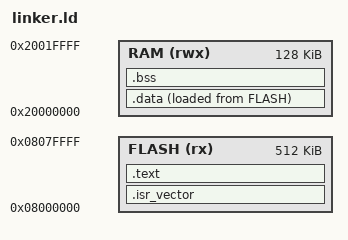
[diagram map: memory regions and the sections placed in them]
ENTRY(_start)

MEMORY
{
    FLASH (rx)  : ORIGIN = 0x08000000, LENGTH = 512K
    RAM   (rwx) : ORIGIN = 0x20000000, LENGTH = 128K
}

SECTIONS
{
    .isr_vector :
    {
        . = ALIGN(4);
        KEEP(*(.isr_vector))
        . = ALIGN(4);
    } > FLASH

    .text :
    {
        . = ALIGN(4);
        *(.text.startup)
        *(.text*)
        *(.rodata*)
        . = ALIGN(4);
    } > FLASH

    .data :
    {
        . = ALIGN(4);
        __data_start__ = .;
        *(.data*)
        . = ALIGN(4);
        __data_end__ = .;
    } > RAM AT > FLASH

    __data_load__ = LOADADDR(.data);

    .bss :
    {
        . = ALIGN(4);
        __bss_start__ = .;
        *(.bss*)
        *(COMMON)
        . = ALIGN(4);
        __bss_end__ = .;
    } > RAM

    . = ALIGN(8);

    _end = .;

    /*
     * Dedicated stack region.
     * Stack grows downward from _stack_top.
     */
    _stack_bottom = 0x20000100;
    _stack_top    = 0x2000F000;

    ASSERT(_end < _stack_bottom,
           "ERROR: .bss/data overlaps stack region")
}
